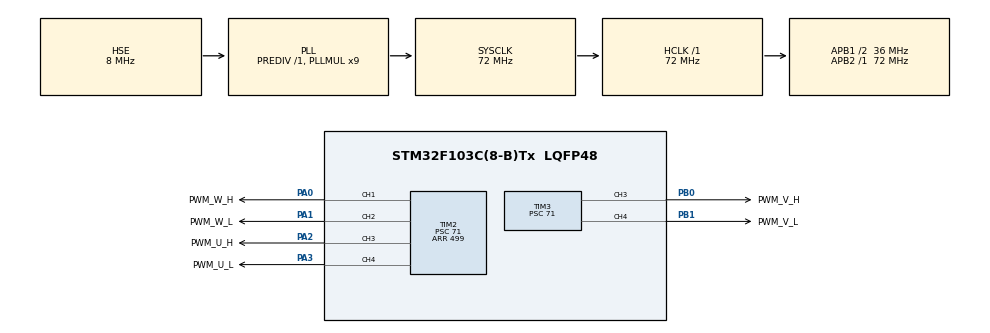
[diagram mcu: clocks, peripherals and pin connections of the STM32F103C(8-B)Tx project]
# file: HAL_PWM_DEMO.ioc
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Mcu.Family=STM32F1
Mcu.Name=STM32F103C(8-B)Tx
Mcu.Package=LQFP48
NVIC.PriorityGroup=NVIC_PRIORITYGROUP_4
PA0-WKUP.GPIO_Label=PWM_W_H
PA0-WKUP.Signal=S_TIM2_CH1_ETR
PA1.GPIO_Label=PWM_W_L
PA1.Signal=S_TIM2_CH2
PA13.Mode=Serial_Wire
PA13.Signal=SYS_JTMS-SWDIO
PA14.Mode=Serial_Wire
PA14.Signal=SYS_JTCK-SWCLK
PA2.GPIO_Label=PWM_U_H
PA2.Signal=S_TIM2_CH3
PA3.GPIO_Label=PWM_U_L
PA3.Signal=S_TIM2_CH4
PB0.GPIO_Label=PWM_V_H
PB0.Signal=S_TIM3_CH3
PB1.GPIO_Label=PWM_V_L
PB1.Signal=S_TIM3_CH4
PC14-OSC32_IN.Mode=LSE-External-Oscillator
PC14-OSC32_IN.Signal=RCC_OSC32_IN
PC15-OSC32_OUT.Mode=LSE-External-Oscillator
PC15-OSC32_OUT.Signal=RCC_OSC32_OUT
PD0-OSC_IN.Mode=HSE-External-Oscillator
PD0-OSC_IN.Signal=RCC_OSC_IN
PD1-OSC_OUT.Mode=HSE-External-Oscillator
PD1-OSC_OUT.Signal=RCC_OSC_OUT
ProjectManager.HeapSize=0x200
ProjectManager.StackSize=0x400
ProjectManager.TargetToolchain=MDK-ARM V5.27
RCC.AHBFreq_Value=72000000
RCC.APB1CLKDivider=RCC_HCLK_DIV2
RCC.APB1Freq_Value=36000000
RCC.APB1TimFreq_Value=72000000
RCC.APB2Freq_Value=72000000
RCC.APB2TimFreq_Value=72000000
RCC.HCLKFreq_Value=72000000
RCC.PLLMUL=RCC_PLL_MUL9
RCC.PLLSourceVirtual=RCC_PLLSOURCE_HSE
RCC.SYSCLKFreq_VALUE=72000000
RCC.SYSCLKSource=RCC_SYSCLKSOURCE_PLLCLK
RCC.USBFreq_Value=72000000
SH.S_TIM2_CH1_ETR.0=TIM2_CH1,PWM Generation1 CH1
SH.S_TIM2_CH2.0=TIM2_CH2,PWM Generation2 CH2
SH.S_TIM2_CH3.0=TIM2_CH3,PWM Generation3 CH3
SH.S_TIM2_CH4.0=TIM2_CH4,PWM Generation4 CH4
SH.S_TIM3_CH3.0=TIM3_CH3,PWM Generation3 CH3
SH.S_TIM3_CH4.0=TIM3_CH4,PWM Generation4 CH4
TIM2.AutoReloadPreload=TIM_AUTORELOAD_PRELOAD_ENABLE
TIM2.Channel-PWM\ Generation1\ CH1=TIM_CHANNEL_1
TIM2.Channel-PWM\ Generation2\ CH2=TIM_CHANNEL_2
TIM2.Channel-PWM\ Generation3\ CH3=TIM_CHANNEL_3
TIM2.Channel-PWM\ Generation4\ CH4=TIM_CHANNEL_4
TIM2.CounterMode=TIM_COUNTERMODE_CENTERALIGNED1
TIM2.OCPolarity_2=TIM_OCPOLARITY_LOW
TIM2.OCPolarity_4=TIM_OCPOLARITY_LOW
TIM2.Period=499
TIM2.Prescaler=71
TIM3.Channel-PWM\ Generation3\ CH3=TIM_CHANNEL_3
TIM3.Channel-PWM\ Generation4\ CH4=TIM_CHANNEL_4
TIM3.CounterMode=TIM_COUNTERMODE_CENTERALIGNED1
TIM3.OCPolarity_4=TIM_OCPOLARITY_LOW
TIM3.Period=499
TIM3.Prescaler=71
board=custom

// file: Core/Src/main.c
/* USER CODE BEGIN Header */
/**
  ******************************************************************************
  * @file           : main.c
  * @brief          : Main program body
  ******************************************************************************
  * @attention
  *
  * <h2><center>&copy; Copyright (c) 2022 STMicroelectronics.
  * All rights reserved.</center></h2>
  *
  * This software component is licensed by ST under BSD 3-Clause license,
  * the "License"; You may not use this file except in compliance with the
  * License. You may obtain a copy of the License at:
  *                        opensource.org/licenses/BSD-3-Clause
  *
  ******************************************************************************
  */
/* USER CODE END Header */
#include "main.h"
#include "tim.h"
#include "gpio.h"

/* USER CODE BEGIN PM */

/******
void PWM_U_OUT(uint16_t duty)
{
	__HAL_TIM_SET_COMPARE(&htim2, TIM_CHANNEL_3, duty);
	__HAL_TIM_SET_COMPARE(&htim2, TIM_CHANNEL_4, duty);
}

void PWM_V_OUT(uint16_t duty)
{
	__HAL_TIM_SET_COMPARE(&htim3, TIM_CHANNEL_3, duty);
	__HAL_TIM_SET_COMPARE(&htim3, TIM_CHANNEL_4, duty);
}

void PWM_W_OUT(uint16_t duty)
{
	__HAL_TIM_SET_COMPARE(&htim2, TIM_CHANNEL_1, duty);
	__HAL_TIM_SET_COMPARE(&htim2, TIM_CHANNEL_2, duty);
}

***********/

/* USER CODE END PM */

void SystemClock_Config(void);

int main(void)
{

  /* MCU Configuration--------------------------------------------------------*/

  /* Reset of all peripherals, Initializes the Flash interface and the Systick. */
  HAL_Init();

  /* Configure the system clock */
  SystemClock_Config();

  /* Initialize all configured peripherals */
  MX_GPIO_Init();
  MX_TIM2_Init();
  MX_TIM3_Init();
  /* USER CODE BEGIN 2 */

  //SET PWM DUTY
  __HAL_TIM_SET_COMPARE(&htim2, TIM_CHANNEL_1, 20);
  __HAL_TIM_SET_COMPARE(&htim2, TIM_CHANNEL_2, 40);
  __HAL_TIM_SET_COMPARE(&htim2, TIM_CHANNEL_3, 50);
  __HAL_TIM_SET_COMPARE(&htim2, TIM_CHANNEL_4, 70);
  __HAL_TIM_SET_COMPARE(&htim3, TIM_CHANNEL_3, 80);
  __HAL_TIM_SET_COMPARE(&htim3, TIM_CHANNEL_4, 90);

  //start pwm
  HAL_TIM_PWM_Start(&htim2, TIM_CHANNEL_1);
  HAL_TIM_PWM_Start(&htim2, TIM_CHANNEL_2);
  HAL_TIM_PWM_Start(&htim2, TIM_CHANNEL_3);
  HAL_TIM_PWM_Start(&htim2, TIM_CHANNEL_4);
  HAL_TIM_PWM_Start(&htim3, TIM_CHANNEL_3);
  HAL_TIM_PWM_Start(&htim3, TIM_CHANNEL_4);

  /* USER CODE END 2 */

  /* Infinite loop */
  while (1)
  {

  }
}

void SystemClock_Config(void)
{
  RCC_OscInitTypeDef RCC_OscInitStruct = {0};
  RCC_ClkInitTypeDef RCC_ClkInitStruct = {0};

  /** Initializes the RCC Oscillators according to the specified parameters
  * in the RCC_OscInitTypeDef structure.
  */
  RCC_OscInitStruct.OscillatorType = RCC_OSCILLATORTYPE_HSE;
  RCC_OscInitStruct.HSEState = RCC_HSE_ON;
  RCC_OscInitStruct.HSEPredivValue = RCC_HSE_PREDIV_DIV1;
  RCC_OscInitStruct.HSIState = RCC_HSI_ON;
  RCC_OscInitStruct.PLL.PLLState = RCC_PLL_ON;
  RCC_OscInitStruct.PLL.PLLSource = RCC_PLLSOURCE_HSE;
  RCC_OscInitStruct.PLL.PLLMUL = RCC_PLL_MUL9;
  if (HAL_RCC_OscConfig(&RCC_OscInitStruct) != HAL_OK)
  {
    Error_Handler();
  }
  /** Initializes the CPU, AHB and APB buses clocks
  */
  RCC_ClkInitStruct.ClockType = RCC_CLOCKTYPE_HCLK|RCC_CLOCKTYPE_SYSCLK
                              |RCC_CLOCKTYPE_PCLK1|RCC_CLOCKTYPE_PCLK2;
  RCC_ClkInitStruct.SYSCLKSource = RCC_SYSCLKSOURCE_PLLCLK;
  RCC_ClkInitStruct.AHBCLKDivider = RCC_SYSCLK_DIV1;
  RCC_ClkInitStruct.APB1CLKDivider = RCC_HCLK_DIV2;
  RCC_ClkInitStruct.APB2CLKDivider = RCC_HCLK_DIV1;

  if (HAL_RCC_ClockConfig(&RCC_ClkInitStruct, FLASH_LATENCY_2) != HAL_OK)
  {
    Error_Handler();
  }
}

void Error_Handler(void)
{
  __disable_irq();
  while (1)
  {
  }
}

/************************ (C) COPYRIGHT STMicroelectronics *****END OF FILE****/
